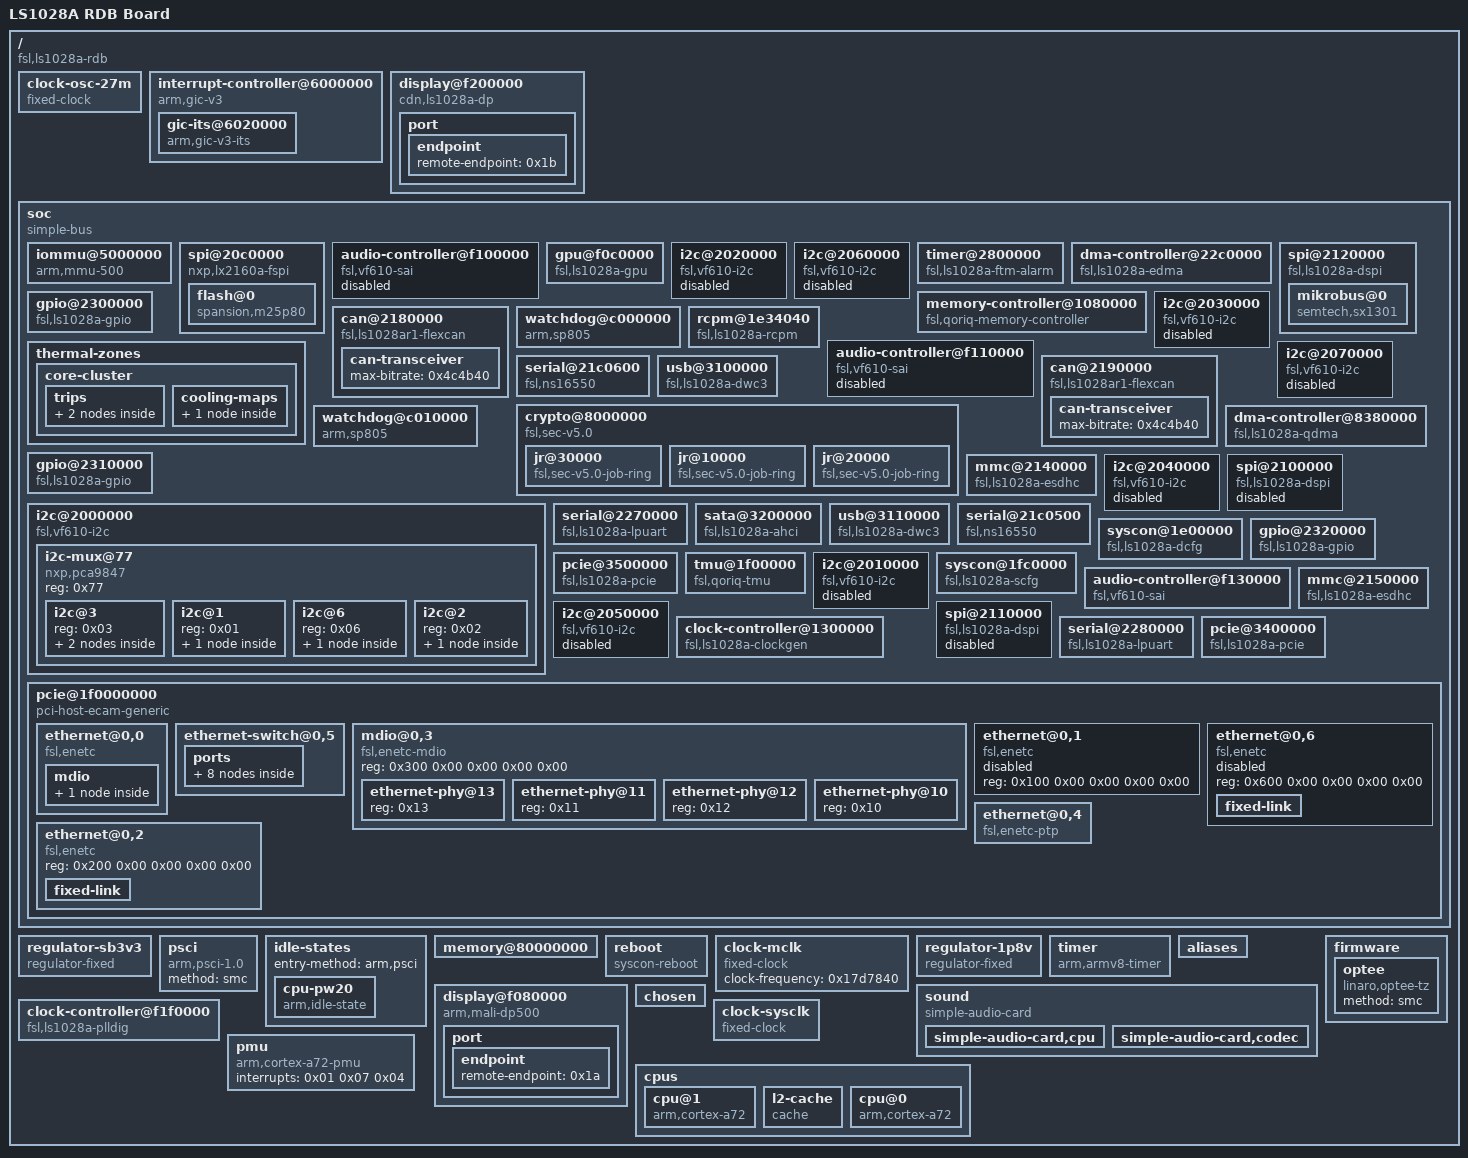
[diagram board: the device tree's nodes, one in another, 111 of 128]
/dts-v1/;

/ {
	#address-cells = <0x02>;
	model = "LS1028A RDB Board";
	#size-cells = <0x02>;
	interrupt-parent = <0x01>;
	compatible = "fsl,ls1028a-rdb\0fsl,ls1028a";

	clock-osc-27m {
		clock-output-names = "phy_27m";
		#clock-cells = <0x00>;
		clock-frequency = <0x19bfcc0>;
		compatible = "fixed-clock";
		phandle = <0x05>;
	};

	interrupt-controller@6000000 {
		#address-cells = <0x02>;
		interrupts = <0x01 0x09 0xf08>;
		#size-cells = <0x02>;
		compatible = "arm,gic-v3";
		ranges;
		#interrupt-cells = <0x03>;
		reg = <0x00 0x6000000 0x00 0x10000 0x00 0x6040000 0x00 0x40000>;
		phandle = <0x01>;
		interrupt-controller;

		gic-its@6020000 {
			msi-controller;
			compatible = "arm,gic-v3-its";
			reg = <0x00 0x6020000 0x00 0x20000>;
			phandle = <0x11>;
		};
	};

	display@f200000 {
		clock-names = "clk_core\0pclk\0sclk\0cclk\0clk_vif\0clk_pxl";
		interrupts = <0x00 0xdd 0x04>;
		clocks = <0x02 0x02 0x02 0x02 0x02 0x02 0x02 0x02 0x02 0x02 0x02 0x02 0x02 0x02 0x02 0x19>;
		compatible = "cdn,ls1028a-dp";
		status = "okay";
		reg = <0x00 0xf200000 0x00 0xfffff>;
		lane-mapping = <0x4e>;

		port {

			endpoint {
				remote-endpoint = <0x1b>;
				phandle = <0x1a>;
			};
		};
	};

	soc {
		#address-cells = <0x02>;
		#size-cells = <0x02>;
		compatible = "simple-bus";
		ranges;

		iommu@5000000 {
			#global-interrupts = <0x08>;
			stream-match-mask = <0x7c00>;
			interrupts = <0x00 0x0d 0x04 0x00 0x0e 0x04 0x00 0x0f 0x04 0x00 0x10 0x04 0x00 0xd3 0x04 0x00 0xd4 0x04 0x00 0xd5 0x04 0x00 0xd6 0x04 0x00 0x92 0x04 0x00 0x93 0x04 0x00 0x94 0x04 0x00 0x95 0x04 0x00 0x96 0x04 0x00 0x97 0x04 0x00 0x98 0x04 0x00 0x99 0x04 0x00 0x9a 0x04 0x00 0x9b 0x04 0x00 0x9c 0x04 0x00 0x9d 0x04 0x00 0x9e 0x04 0x00 0x9f 0x04 0x00 0xa0 0x04 0x00 0xa1 0x04 0x00 0xa2 0x04 0x00 0xa3 0x04 0x00 0xa4 0x04 0x00 0xa5 0x04 0x00 0xa6 0x04 0x00 0xa7 0x04 0x00 0xa8 0x04 0x00 0xa9 0x04 0x00 0xaa 0x04 0x00 0xab 0x04 0x00 0xac 0x04 0x00 0xad 0x04 0x00 0xae 0x04 0x00 0xaf 0x04 0x00 0xb0 0x04 0x00 0xb1 0x04 0x00 0xb2 0x04 0x00 0xb3 0x04 0x00 0xb4 0x04 0x00 0xb5 0x04 0x00 0xb6 0x04 0x00 0xb7 0x04 0x00 0xb8 0x04 0x00 0xb9 0x04 0x00 0xba 0x04 0x00 0xbb 0x04 0x00 0xbc 0x04 0x00 0xbd 0x04 0x00 0xbe 0x04 0x00 0xbf 0x04 0x00 0xc0 0x04 0x00 0xc1 0x04 0x00 0xc2 0x04 0x00 0xc3 0x04 0x00 0xc4 0x04 0x00 0xc5 0x04 0x00 0xc6 0x04 0x00 0xc7 0x04 0x00 0xc8 0x04 0x00 0xc9 0x04 0x00 0xca 0x04 0x00 0xcb 0x04 0x00 0xcc 0x04 0x00 0xcd 0x04 0x00 0xce 0x04 0x00 0xcf 0x04 0x00 0xd0 0x04 0x00 0xd1 0x04>;
			#iommu-cells = <0x01>;
			compatible = "arm,mmu-500";
			reg = <0x00 0x5000000 0x00 0x800000>;
			phandle = <0x10>;
		};

		spi@20c0000 {
			#address-cells = <0x01>;
			clock-names = "fspi_en\0fspi";
			reg-names = "fspi_base\0fspi_mmap";
			interrupts = <0x00 0x19 0x04>;
			clocks = <0x02 0x04 0x03 0x02 0x04 0x03>;
			#size-cells = <0x00>;
			compatible = "nxp,lx2160a-fspi";
			status = "okay";
			reg = <0x00 0x20c0000 0x00 0x10000 0x00 0x20000000 0x00 0x10000000>;

			flash@0 {
				m25p,fast-read;
				#address-cells = <0x01>;
				spi-tx-bus-width = <0x01>;
				#size-cells = <0x01>;
				spi-max-frequency = <0x1312d00>;
				spi-rx-bus-width = <0x08>;
				compatible = "spansion,m25p80";
				reg = <0x00>;
			};
		};

		audio-controller@f100000 {
			clock-names = "bus\0mclk0\0mclk1\0mclk2\0mclk3";
			interrupts = <0x00 0x52 0x04>;
			clocks = <0x02 0x04 0x01 0x02 0x04 0x01 0x02 0x04 0x01 0x02 0x04 0x01 0x02 0x04 0x01>;
			dma-names = "tx\0rx";
			#sound-dai-cells = <0x00>;
			compatible = "fsl,vf610-sai";
			status = "disabled";
			reg = <0x00 0xf100000 0x00 0x10000>;
			dmas = <0x08 0x01 0x04 0x08 0x01 0x03>;
		};

		gpu@f0c0000 {
			iommus = <0x10 0x47>;
			reg-names = "base\0phys_baseaddr\0contiguous_mem";
			interrupts = <0x00 0xdc 0x04>;
			compatible = "fsl,ls1028a-gpu";
			reg = <0x00 0xf0c0000 0x00 0x10000 0x00 0x80000000 0x00 0x80000000 0x00 0x00 0x00 0x3000000>;
		};

		i2c@2020000 {
			#address-cells = <0x01>;
			interrupts = <0x00 0x23 0x04>;
			clocks = <0x02 0x04 0x03>;
			#size-cells = <0x00>;
			compatible = "fsl,vf610-i2c";
			status = "disabled";
			reg = <0x00 0x2020000 0x00 0x10000>;
		};

		i2c@2060000 {
			#address-cells = <0x01>;
			interrupts = <0x00 0x4b 0x04>;
			clocks = <0x02 0x04 0x03>;
			#size-cells = <0x00>;
			compatible = "fsl,vf610-i2c";
			status = "disabled";
			reg = <0x00 0x2060000 0x00 0x10000>;
		};

		timer@2800000 {
			fsl,rcpm-wakeup = <0x18 0x00 0x00 0x00 0x00 0x4000 0x00 0x00>;
			interrupts = <0x00 0x2c 0x04>;
			compatible = "fsl,ls1028a-ftm-alarm";
			reg = <0x00 0x2800000 0x00 0x10000>;
		};

		dma-controller@22c0000 {
			clock-names = "dmamux0\0dmamux1";
			interrupts = <0x00 0x38 0x04 0x00 0x38 0x04>;
			clocks = <0x02 0x04 0x01 0x02 0x04 0x01>;
			compatible = "fsl,ls1028a-edma";
			interrupt-names = "edma-tx\0edma-err";
			reg = <0x00 0x22c0000 0x00 0x10000 0x00 0x22d0000 0x00 0x10000 0x00 0x22e0000 0x00 0x10000>;
			phandle = <0x08>;
			dma-channels = <0x20>;
			#dma-cells = <0x02>;
		};

		memory-controller@1080000 {
			big-endian;
			interrupts = <0x00 0x90 0x04>;
			compatible = "fsl,qoriq-memory-controller";
			reg = <0x00 0x1080000 0x00 0x1000>;
		};

		spi@2120000 {
			#address-cells = <0x01>;
			little-endian;
			clock-names = "dspi";
			spi-num-chipselects = <0x03>;
			interrupts = <0x00 0x1a 0x04>;
			clocks = <0x02 0x04 0x01>;
			#size-cells = <0x00>;
			dma-names = "tx\0rx";
			compatible = "fsl,ls1028a-dspi\0fsl,ls1021a-v1.0-dspi";
			status = "okay";
			bus-num = <0x02>;
			reg = <0x00 0x2120000 0x00 0x10000>;
			dmas = <0x08 0x00 0x36 0x08 0x00 0x02>;

			mikrobus@0 {
				fsl,spi-sck-cs-delay = <0x32>;
				fsl,spi-cs-sck-delay = <0xf4240>;
				spi-max-frequency = <0x1e8480>;
				compatible = "semtech,sx1301";
				reg = <0x00>;
			};
		};

		can@2180000 {
			clock-names = "ipg\0per";
			interrupts = <0x00 0x15 0x04>;
			clocks = <0x07 0x02 0x04 0x01>;
			compatible = "fsl,ls1028ar1-flexcan\0fsl,lx2160ar1-flexcan";
			status = "okay";
			reg = <0x00 0x2180000 0x00 0x10000>;

			can-transceiver {
				max-bitrate = <0x4c4b40>;
			};
		};

		watchdog@c000000 {
			clock-names = "apb_pclk\0wdog_clk";
			clocks = <0x02 0x04 0x0f 0x02 0x04 0x0f>;
			compatible = "arm,sp805\0arm,primecell";
			reg = <0x00 0xc000000 0x00 0x1000>;
		};

		gpio@2300000 {
			little-endian;
			gpio-controller;
			interrupts = <0x00 0x24 0x04>;
			compatible = "fsl,ls1028a-gpio\0fsl,qoriq-gpio";
			#interrupt-cells = <0x02>;
			reg = <0x00 0x2300000 0x00 0x10000>;
			#gpio-cells = <0x02>;
			interrupt-controller;
		};

		rcpm@1e34040 {
			little-endian;
			#fsl,rcpm-wakeup-cells = <0x07>;
			compatible = "fsl,ls1028a-rcpm\0fsl,qoriq-rcpm-2.1+";
			reg = <0x00 0x1e34040 0x00 0x1c>;
			phandle = <0x18>;
		};

		audio-controller@f110000 {
			clock-names = "bus\0mclk0\0mclk1\0mclk2\0mclk3";
			interrupts = <0x00 0x52 0x04>;
			clocks = <0x02 0x04 0x01 0x02 0x04 0x01 0x02 0x04 0x01 0x02 0x04 0x01 0x02 0x04 0x01>;
			dma-names = "tx\0rx";
			#sound-dai-cells = <0x00>;
			compatible = "fsl,vf610-sai";
			status = "disabled";
			reg = <0x00 0xf110000 0x00 0x10000>;
			dmas = <0x08 0x01 0x06 0x08 0x01 0x05>;
		};

		i2c@2030000 {
			#address-cells = <0x01>;
			interrupts = <0x00 0x23 0x04>;
			clocks = <0x02 0x04 0x03>;
			#size-cells = <0x00>;
			compatible = "fsl,vf610-i2c";
			status = "disabled";
			reg = <0x00 0x2030000 0x00 0x10000>;
		};

		thermal-zones {

			core-cluster {
				polling-delay = <0x1388>;
				polling-delay-passive = <0x3e8>;
				thermal-sensors = <0x0c 0x00>;

				trips {

					core-cluster-crit {
						temperature = <0x17318>;
						hysteresis = <0x7d0>;
						type = "critical";
					};

					core-cluster-alert {
						temperature = <0x14c08>;
						hysteresis = <0x7d0>;
						type = "passive";
						phandle = <0x0d>;
					};
				};

				cooling-maps {

					map0 {
						trip = <0x0d>;
						cooling-device = <0x0e 0xffffffff 0xffffffff 0x0f 0xffffffff 0xffffffff>;
					};
				};
			};
		};

		i2c@2070000 {
			#address-cells = <0x01>;
			interrupts = <0x00 0x4b 0x04>;
			clocks = <0x02 0x04 0x03>;
			#size-cells = <0x00>;
			compatible = "fsl,vf610-i2c";
			status = "disabled";
			reg = <0x00 0x2070000 0x00 0x10000>;
		};

		serial@21c0600 {
			interrupts = <0x00 0x20 0x04>;
			clocks = <0x02 0x04 0x01>;
			clock-frequency = <0xbebc200>;
			compatible = "fsl,ns16550\0ns16550a";
			status = "okay";
			reg = <0x00 0x21c0600 0x00 0x100>;
		};

		usb@3100000 {
			iommus = <0x10 0x01>;
			dma-coherent;
			snps,incr-burst-type-adjustment = <0x01 0x04 0x08 0x10>;
			snps,quirk-frame-length-adjustment = <0x20>;
			interrupts = <0x00 0x50 0x04>;
			snps,dis_rxdet_inp3_quirk;
			compatible = "fsl,ls1028a-dwc3\0snps,dwc3";
			reg = <0x00 0x3100000 0x00 0x10000>;
			dr_mode = "host";
		};

		can@2190000 {
			clock-names = "ipg\0per";
			interrupts = <0x00 0x16 0x04>;
			clocks = <0x07 0x02 0x04 0x01>;
			compatible = "fsl,ls1028ar1-flexcan\0fsl,lx2160ar1-flexcan";
			status = "okay";
			reg = <0x00 0x2190000 0x00 0x10000>;

			can-transceiver {
				max-bitrate = <0x4c4b40>;
			};
		};

		crypto@8000000 {
			#address-cells = <0x01>;
			dma-coherent;
			fsl,sec-era = <0x0a>;
			interrupts = <0x00 0x8b 0x04>;
			#size-cells = <0x01>;
			compatible = "fsl,sec-v5.0\0fsl,sec-v4.0";
			ranges = <0x00 0x00 0x8000000 0x100000>;
			reg = <0x00 0x8000000 0x00 0x100000>;

			jr@30000 {
				iommus = <0x10 0x43>;
				interrupts = <0x00 0x8e 0x04>;
				compatible = "fsl,sec-v5.0-job-ring\0fsl,sec-v4.0-job-ring";
				reg = <0x30000 0x10000>;
			};

			jr@10000 {
				iommus = <0x10 0x41>;
				interrupts = <0x00 0x8c 0x04>;
				compatible = "fsl,sec-v5.0-job-ring\0fsl,sec-v4.0-job-ring";
				reg = <0x10000 0x10000>;
			};

			jr@20000 {
				iommus = <0x10 0x42>;
				interrupts = <0x00 0x8d 0x04>;
				compatible = "fsl,sec-v5.0-job-ring\0fsl,sec-v4.0-job-ring";
				reg = <0x20000 0x10000>;
			};
		};

		dma-controller@8380000 {
			iommus = <0x10 0x05>;
			block-offset = <0x10000>;
			block-number = <0x01>;
			status-sizes = <0x40>;
			interrupts = <0x00 0x2b 0x04 0x00 0xfb 0x04 0x00 0xfc 0x04 0x00 0xfd 0x04 0x00 0xfe 0x04>;
			compatible = "fsl,ls1028a-qdma\0fsl,ls1021a-qdma";
			fsl,dma-queues = <0x02>;
			interrupt-names = "qdma-error\0qdma-queue0\0qdma-queue1\0qdma-queue2\0qdma-queue3";
			reg = <0x00 0x8380000 0x00 0x1000 0x00 0x8390000 0x00 0x10000 0x00 0x83a0000 0x00 0x40000>;
			dma-channels = <0x08>;
			queue-sizes = <0x40 0x40>;
		};

		watchdog@c010000 {
			clock-names = "apb_pclk\0wdog_clk";
			clocks = <0x02 0x04 0x0f 0x02 0x04 0x0f>;
			compatible = "arm,sp805\0arm,primecell";
			reg = <0x00 0xc010000 0x00 0x1000>;
		};

		gpio@2310000 {
			little-endian;
			gpio-controller;
			interrupts = <0x00 0x24 0x04>;
			compatible = "fsl,ls1028a-gpio\0fsl,qoriq-gpio";
			#interrupt-cells = <0x02>;
			reg = <0x00 0x2310000 0x00 0x10000>;
			#gpio-cells = <0x02>;
			interrupt-controller;
		};

		i2c@2000000 {
			#address-cells = <0x01>;
			interrupts = <0x00 0x22 0x04>;
			clocks = <0x02 0x04 0x03>;
			#size-cells = <0x00>;
			compatible = "fsl,vf610-i2c";
			status = "okay";
			reg = <0x00 0x2000000 0x00 0x10000>;

			i2c-mux@77 {
				#address-cells = <0x01>;
				#size-cells = <0x00>;
				compatible = "nxp,pca9847";
				reg = <0x77>;

				i2c@3 {
					#address-cells = <0x01>;
					#size-cells = <0x00>;
					reg = <0x03>;

					temperature-sensor@4c {
						compatible = "nxp,sa56004";
						reg = <0x4c>;
						vcc-supply = <0x0b>;
					};

					m41t62@68 {
						compatible = "st,m41t62";
						reg = <0x68>;
					};
				};

				i2c@1 {
					#address-cells = <0x01>;
					#size-cells = <0x00>;
					reg = <0x01>;

					audio-codec@a {
						sclk-strength = <0x03>;
						VDDA-supply = <0x09>;
						clocks = <0x0a>;
						#sound-dai-cells = <0x00>;
						VDDIO-supply = <0x09>;
						compatible = "fsl,sgtl5000";
						reg = <0x0a>;
						phandle = <0x1d>;
					};
				};

				i2c@6 {
					#address-cells = <0x01>;
					#size-cells = <0x00>;
					reg = <0x06>;

					pn7120@28 {
						clock-frequency = <0xf4240>;
						compatible = "nxp,pn7120\0nxp,pn544";
						reg = <0x28>;
					};
				};

				i2c@2 {
					#address-cells = <0x01>;
					#size-cells = <0x00>;
					reg = <0x02>;

					current-monitor@40 {
						compatible = "ti,ina220";
						reg = <0x40>;
						shunt-resistor = <0x1f4>;
					};
				};
			};
		};

		mmc@2140000 {
			iommus = <0x10 0x03>;
			sdhci,auto-cmd12;
			little-endian;
			sd-uhs-sdr25;
			bus-width = <0x04>;
			interrupts = <0x00 0x1c 0x04>;
			clocks = <0x02 0x02 0x01>;
			voltage-ranges = <0x708 0x708 0xce4 0xce4>;
			clock-frequency = <0x17d78400>;
			compatible = "fsl,ls1028a-esdhc\0fsl,esdhc";
			status = "okay";
			reg = <0x00 0x2140000 0x00 0x10000>;
			sd-uhs-sdr104;
			sd-uhs-sdr50;
			sd-uhs-sdr12;
		};

		i2c@2040000 {
			#address-cells = <0x01>;
			interrupts = <0x00 0x4a 0x04>;
			clocks = <0x02 0x04 0x03>;
			#size-cells = <0x00>;
			compatible = "fsl,vf610-i2c";
			status = "disabled";
			reg = <0x00 0x2040000 0x00 0x10000>;
		};

		spi@2100000 {
			#address-cells = <0x01>;
			little-endian;
			clock-names = "dspi";
			spi-num-chipselects = <0x04>;
			interrupts = <0x00 0x1a 0x04>;
			clocks = <0x02 0x04 0x01>;
			#size-cells = <0x00>;
			dma-names = "tx\0rx";
			compatible = "fsl,ls1028a-dspi\0fsl,ls1021a-v1.0-dspi";
			status = "disabled";
			reg = <0x00 0x2100000 0x00 0x10000>;
			dmas = <0x08 0x00 0x3e 0x08 0x00 0x3c>;
		};

		serial@2270000 {
			little-endian;
			clock-names = "ipg";
			interrupts = <0x00 0xe9 0x04>;
			clocks = <0x02 0x04 0x01>;
			compatible = "fsl,ls1028a-lpuart";
			status = "okay";
			reg = <0x00 0x2270000 0x00 0x1000>;
		};

		sata@3200000 {
			iommus = <0x10 0x04>;
			reg-names = "ahci\0sata-ecc";
			interrupts = <0x00 0x85 0x04>;
			clocks = <0x02 0x04 0x01>;
			compatible = "fsl,ls1028a-ahci";
			status = "okay";
			reg = <0x00 0x3200000 0x00 0x10000 0x07 0x100520 0x00 0x04>;
		};

		usb@3110000 {
			iommus = <0x10 0x02>;
			dma-coherent;
			snps,incr-burst-type-adjustment = <0x01 0x04 0x08 0x10>;
			snps,quirk-frame-length-adjustment = <0x20>;
			interrupts = <0x00 0x51 0x04>;
			snps,dis_rxdet_inp3_quirk;
			compatible = "fsl,ls1028a-dwc3\0snps,dwc3";
			reg = <0x00 0x3110000 0x00 0x10000>;
			dr_mode = "otg";
		};

		serial@21c0500 {
			interrupts = <0x00 0x20 0x04>;
			clocks = <0x02 0x04 0x01>;
			clock-frequency = <0xbebc200>;
			compatible = "fsl,ns16550\0ns16550a";
			status = "okay";
			reg = <0x00 0x21c0500 0x00 0x100>;
		};

		syscon@1e00000 {
			little-endian;
			compatible = "fsl,ls1028a-dcfg\0syscon";
			reg = <0x00 0x1e00000 0x00 0x10000>;
			phandle = <0x06>;
		};

		gpio@2320000 {
			little-endian;
			gpio-controller;
			interrupts = <0x00 0x25 0x04>;
			compatible = "fsl,ls1028a-gpio\0fsl,qoriq-gpio";
			#interrupt-cells = <0x02>;
			reg = <0x00 0x2320000 0x00 0x10000>;
			#gpio-cells = <0x02>;
			interrupt-controller;
		};

		pcie@3500000 {
			#address-cells = <0x03>;
			dma-coherent;
			bus-range = <0x00 0xff>;
			reg-names = "regs\0config";
			interrupts = <0x00 0x71 0x04 0x00 0x72 0x04>;
			interrupt-map = <0x00 0x00 0x00 0x01 0x01 0x00 0x00 0x00 0x72 0x04 0x00 0x00 0x00 0x02 0x01 0x00 0x00 0x00 0x73 0x04 0x00 0x00 0x00 0x03 0x01 0x00 0x00 0x00 0x74 0x04 0x00 0x00 0x00 0x04 0x01 0x00 0x00 0x00 0x75 0x04>;
			#size-cells = <0x02>;
			device_type = "pci";
			interrupt-map-mask = <0x00 0x00 0x00 0x07>;
			compatible = "fsl,ls1028a-pcie";
			ranges = <0x81000000 0x00 0x00 0x88 0x10000 0x00 0x10000 0x82000000 0x00 0x40000000 0x88 0x40000000 0x00 0x40000000>;
			msi-map = <0x00 0x11 0x08 0x01 0x100 0x11 0x09 0x01>;
			#interrupt-cells = <0x01>;
			status = "okay";
			interrupt-names = "pme\0aer";
			reg = <0x00 0x3500000 0x00 0x100000 0x88 0x00 0x00 0x2000>;
			iommu-map = <0x00 0x10 0x08 0x01 0x100 0x10 0x09 0x01>;
			msi-parent = <0x11>;
		};

		tmu@1f00000 {
			little-endian;
			fsl,tmu-calibration = <0x00 0x24 0x01 0x2b 0x02 0x31 0x03 0x38 0x04 0x3f 0x05 0x45 0x06 0x4c 0x07 0x53 0x08 0x59 0x09 0x60 0x0a 0x66 0x0b 0x6d 0x10000 0x1c 0x10001 0x24 0x10002 0x2c 0x10003 0x35 0x10004 0x3d 0x10005 0x45 0x10006 0x4d 0x10007 0x55 0x10008 0x5e 0x10009 0x66 0x1000a 0x6e 0x20000 0x18 0x20001 0x22 0x20002 0x2d 0x20003 0x38 0x20004 0x43 0x20005 0x4d 0x20006 0x58 0x20007 0x63 0x20008 0x6e 0x30000 0x10 0x30001 0x1c 0x30002 0x29 0x30003 0x36 0x30004 0x42 0x30005 0x4f 0x30006 0x5b 0x30007 0x68>;
			fsl,tmu-range = <0xb0000 0xa0026 0x80048 0x70061>;
			interrupts = <0x00 0x17 0x04>;
			#thermal-sensor-cells = <0x01>;
			compatible = "fsl,qoriq-tmu";
			reg = <0x00 0x1f80000 0x00 0x10000>;
			phandle = <0x0c>;
		};

		i2c@2010000 {
			#address-cells = <0x01>;
			interrupts = <0x00 0x22 0x04>;
			clocks = <0x02 0x04 0x03>;
			#size-cells = <0x00>;
			compatible = "fsl,vf610-i2c";
			status = "disabled";
			reg = <0x00 0x2010000 0x00 0x10000>;
		};

		syscon@1fc0000 {
			big-endian;
			compatible = "fsl,ls1028a-scfg\0syscon";
			reg = <0x00 0x1fc0000 0x00 0x10000>;
		};

		audio-controller@f130000 {
			clock-names = "bus\0mclk0\0mclk1\0mclk2\0mclk3";
			interrupts = <0x00 0x53 0x04>;
			clocks = <0x02 0x04 0x01 0x02 0x04 0x01 0x02 0x04 0x01 0x02 0x04 0x01 0x02 0x04 0x01>;
			dma-names = "tx\0rx";
			#sound-dai-cells = <0x00>;
			compatible = "fsl,vf610-sai";
			status = "okay";
			reg = <0x00 0xf130000 0x00 0x10000>;
			phandle = <0x1c>;
			dmas = <0x08 0x01 0x0a 0x08 0x01 0x09>;
		};

		mmc@2150000 {
			iommus = <0x10 0x45>;
			sdhci,auto-cmd12;
			little-endian;
			mmc-hs200-1_8v;
			bus-width = <0x08>;
			mmc-hs400-1_8v;
			interrupts = <0x00 0x3f 0x04>;
			clocks = <0x02 0x02 0x01>;
			broken-cd;
			voltage-ranges = <0x708 0x708 0xce4 0xce4>;
			clock-frequency = <0x17d78400>;
			compatible = "fsl,ls1028a-esdhc\0fsl,esdhc";
			status = "okay";
			reg = <0x00 0x2150000 0x00 0x10000>;
		};

		i2c@2050000 {
			#address-cells = <0x01>;
			interrupts = <0x00 0x4a 0x04>;
			clocks = <0x02 0x04 0x03>;
			#size-cells = <0x00>;
			compatible = "fsl,vf610-i2c";
			status = "disabled";
			reg = <0x00 0x2050000 0x00 0x10000>;
		};

		clock-controller@1300000 {
			clocks = <0x07>;
			#clock-cells = <0x02>;
			compatible = "fsl,ls1028a-clockgen";
			reg = <0x00 0x1300000 0x00 0xa0000>;
			phandle = <0x02>;
		};

		spi@2110000 {
			#address-cells = <0x01>;
			little-endian;
			clock-names = "dspi";
			spi-num-chipselects = <0x04>;
			interrupts = <0x00 0x1a 0x04>;
			clocks = <0x02 0x04 0x01>;
			#size-cells = <0x00>;
			dma-names = "tx\0rx";
			compatible = "fsl,ls1028a-dspi\0fsl,ls1021a-v1.0-dspi";
			status = "disabled";
			reg = <0x00 0x2110000 0x00 0x10000>;
			dmas = <0x08 0x00 0x3a 0x08 0x00 0x38>;
		};

		serial@2280000 {
			little-endian;
			clock-names = "ipg";
			interrupts = <0x00 0xea 0x04>;
			clocks = <0x02 0x04 0x01>;
			compatible = "fsl,ls1028a-lpuart";
			status = "okay";
			reg = <0x00 0x2280000 0x00 0x1000>;
		};

		pcie@3400000 {
			#address-cells = <0x03>;
			dma-coherent;
			bus-range = <0x00 0xff>;
			reg-names = "regs\0config";
			interrupts = <0x00 0x6c 0x04 0x00 0x6d 0x04>;
			interrupt-map = <0x00 0x00 0x00 0x01 0x01 0x00 0x00 0x00 0x6d 0x04 0x00 0x00 0x00 0x02 0x01 0x00 0x00 0x00 0x6e 0x04 0x00 0x00 0x00 0x03 0x01 0x00 0x00 0x00 0x6f 0x04 0x00 0x00 0x00 0x04 0x01 0x00 0x00 0x00 0x70 0x04>;
			#size-cells = <0x02>;
			device_type = "pci";
			interrupt-map-mask = <0x00 0x00 0x00 0x07>;
			compatible = "fsl,ls1028a-pcie";
			ranges = <0x81000000 0x00 0x00 0x80 0x10000 0x00 0x10000 0x82000000 0x00 0x40000000 0x80 0x40000000 0x00 0x40000000>;
			msi-map = <0x00 0x11 0x07 0x01>;
			#interrupt-cells = <0x01>;
			status = "okay";
			interrupt-names = "pme\0aer";
			reg = <0x00 0x3400000 0x00 0x100000 0x80 0x00 0x00 0x2000>;
			iommu-map = <0x00 0x10 0x07 0x01>;
			msi-parent = <0x11>;
		};

		pcie@1f0000000 {
			#address-cells = <0x03>;
			dma-coherent;
			bus-range = <0x00 0x00>;
			#size-cells = <0x02>;
			device_type = "pci";
			compatible = "pci-host-ecam-generic";
			ranges = <0x82000000 0x00 0x00 0x01 0xf8000000 0x00 0x160000 0xc2000000 0x00 0x00 0x01 0xf8160000 0x00 0x70000 0x82000000 0x00 0x00 0x01 0xf81d0000 0x00 0x20000 0xc2000000 0x00 0x00 0x01 0xf81f0000 0x00 0x20000 0x82000000 0x00 0x00 0x01 0xf8210000 0x00 0x20000 0xc2000000 0x00 0x00 0x01 0xf8230000 0x00 0x20000 0x82000000 0x00 0x00 0x01 0xfc000000 0x00 0x400000>;
			msi-map = <0x00 0x11 0x20 0x0c>;
			reg = <0x01 0xf0000000 0x00 0x100000>;
			iommu-map = <0x00 0x10 0x20 0x0c>;
			msi-parent = <0x11>;

			ethernet@0,0 {
				phy-connection-type = "sgmii";
				compatible = "fsl,enetc";
				reg = <0x00 0x00 0x00 0x00 0x00>;
				phy-handle = <0x12>;

				mdio {
					#address-cells = <0x01>;
					#size-cells = <0x00>;

					ethernet-phy@2 {
						reg = <0x02>;
						phandle = <0x12>;
					};
				};
			};

			ethernet-switch@0,5 {
				interrupts = <0x00 0x5f 0x04>;
				status = "okay";
				reg = <0x500 0x00 0x00 0x00 0x00>;

				ports {
					#address-cells = <0x01>;
					#size-cells = <0x00>;

					port@0 {
						phy-mode = "qsgmii";
						label = "swp0";
						status = "okay";
						managed = "in-band-status";
						reg = <0x00>;
						phy-handle = <0x13>;
					};

					port@5 {
						phy-mode = "internal";
						status = "disabled";
						reg = <0x05>;

						fixed-link {
							full-duplex;
							speed = <0x3e8>;
						};
					};

					port@3 {
						phy-mode = "qsgmii";
						label = "swp3";
						status = "okay";
						managed = "in-band-status";
						reg = <0x03>;
						phy-handle = <0x16>;
					};

					port@1 {
						phy-mode = "qsgmii";
						label = "swp1";
						status = "okay";
						managed = "in-band-status";
						reg = <0x01>;
						phy-handle = <0x14>;
					};

					port@4 {
						phy-mode = "internal";
						reg = <0x04>;
						ethernet = <0x17>;

						fixed-link {
							full-duplex;
							speed = <0x9c4>;
						};
					};

					port@2 {
						phy-mode = "qsgmii";
						label = "swp2";
						status = "okay";
						managed = "in-band-status";
						reg = <0x02>;
						phy-handle = <0x15>;
					};
				};
			};

			mdio@0,3 {
				#address-cells = <0x01>;
				#size-cells = <0x00>;
				compatible = "fsl,enetc-mdio";
				reg = <0x300 0x00 0x00 0x00 0x00>;

				ethernet-phy@13 {
					reg = <0x13>;
					phandle = <0x16>;
				};

				ethernet-phy@11 {
					reg = <0x11>;
					phandle = <0x14>;
				};

				ethernet-phy@12 {
					reg = <0x12>;
					phandle = <0x15>;
				};

				ethernet-phy@10 {
					reg = <0x10>;
					phandle = <0x13>;
				};
			};

			ethernet@0,1 {
				compatible = "fsl,enetc";
				status = "disabled";
				reg = <0x100 0x00 0x00 0x00 0x00>;
			};

			ethernet@0,6 {
				compatible = "fsl,enetc";
				status = "disabled";
				reg = <0x600 0x00 0x00 0x00 0x00>;

				fixed-link {
					full-duplex;
					speed = <0x3e8>;
				};
			};

			ethernet@0,4 {
				little-endian;
				clocks = <0x02 0x04 0x00>;
				compatible = "fsl,enetc-ptp";
				reg = <0x400 0x00 0x00 0x00 0x00>;
			};

			ethernet@0,2 {
				compatible = "fsl,enetc";
				reg = <0x200 0x00 0x00 0x00 0x00>;
				phandle = <0x17>;

				fixed-link {
					full-duplex;
					speed = <0x3e8>;
				};
			};
		};
	};

	regulator-sb3v3 {
		regulator-max-microvolt = <0x325aa0>;
		regulator-boot-on;
		regulator-always-on;
		regulator-min-microvolt = <0x325aa0>;
		regulator-name = "3v3_vbus";
		compatible = "regulator-fixed";
		phandle = <0x0b>;
	};

	psci {
		method = "smc";
		compatible = "arm,psci-1.0\0arm,psci-0.2";
		status = "okay";
	};

	idle-states {
		entry-method = "arm,psci";

		cpu-pw20 {
			entry-latency-us = <0x7d0>;
			idle-state-name = "PW20";
			exit-latency-us = <0x7d0>;
			arm,psci-suspend-param = <0x00>;
			compatible = "arm,idle-state";
			phandle = <0x04>;
			min-residency-us = <0x1770>;
		};
	};

	memory@80000000 {
		device_type = "memory";
		reg = <0x00 0x80000000 0x00 0x7be00000 0x20 0x80000000 0x00 0x80000000>;
	};

	reboot {
		mask = <0x02>;
		offset = <0xb0>;
		compatible = "syscon-reboot";
		regmap = <0x06>;
	};

	clock-mclk {
		#clock-cells = <0x00>;
		clock-frequency = <0x17d7840>;
		compatible = "fixed-clock";
		phandle = <0x0a>;
	};

	regulator-1p8v {
		regulator-max-microvolt = <0x1b7740>;
		regulator-always-on;
		regulator-min-microvolt = <0x1b7740>;
		regulator-name = "1P8V";
		compatible = "regulator-fixed";
		phandle = <0x09>;
	};

	timer {
		interrupts = <0x01 0x0d 0x308 0x01 0x0e 0x308 0x01 0x0b 0x308 0x01 0x0a 0x308>;
		compatible = "arm,armv8-timer";
	};

	aliases {
		crypto = "/soc/crypto@8000000";
		serial1 = "/soc/serial@21c0600";
		rtc1 = "/soc/timer@2800000";
		serial0 = "/soc/serial@21c0500";
	};

	sound {
		simple-audio-card,format = "i2s";
		simple-audio-card,widgets = "Microphone\0Microphone Jack\0Headphone\0Headphone Jack\0Speaker\0Speaker Ext\0Line\0Line In Jack";
		simple-audio-card,routing = "MIC_IN\0Microphone Jack\0Microphone Jack\0Mic Bias\0LINE_IN\0Line In Jack\0Headphone Jack\0HP_OUT\0Speaker Ext\0LINE_OUT";
		compatible = "simple-audio-card";

		simple-audio-card,cpu {
			frame-master;
			bitclock-master;
			sound-dai = <0x1c>;
		};

		simple-audio-card,codec {
			frame-master;
			bitclock-master;
			sound-dai = <0x1d>;
			system-clock-frequency = <0x17d7840>;
		};
	};

	firmware {

		optee {
			method = "smc";
			compatible = "linaro,optee-tz";
		};
	};

	display@f080000 {
		iommus = <0x10 0x48>;
		arm,malidp-output-port-lines = [08 08 08];
		clock-names = "pxlclk\0mclk\0aclk\0pclk";
		interrupts = <0x00 0xde 0x04 0x00 0xdf 0x04>;
		clocks = <0x19 0x02 0x02 0x02 0x02 0x02 0x02 0x02 0x02 0x02>;
		arm,malidp-arqos-value = <0xd000d000>;
		compatible = "arm,mali-dp500";
		interrupt-names = "DE\0SE";
		reg = <0x00 0xf080000 0x00 0x10000>;

		port {

			endpoint {
				remote-endpoint = <0x1a>;
				phandle = <0x1b>;
			};
		};
	};

	clock-controller@f1f0000 {
		clocks = <0x05>;
		#clock-cells = <0x00>;
		compatible = "fsl,ls1028a-plldig";
		reg = <0x00 0xf1f0000 0x00 0xffff>;
		phandle = <0x19>;
	};

	chosen {
		bootargs = "root=/dev/mmcblk1p2 rootwait rw earlycon=uart8250,0x21c0500 console=ttyS0,115200 cma=256M video=1920x1080-32@60";
		kaslr-seed = <0x00 0x00>;
		linux,stdout-path = "/soc/serial@21c0500";
		stdout-path = "serial0:115200n8";
	};

	clock-sysclk {
		clock-output-names = "sysclk";
		#clock-cells = <0x00>;
		clock-frequency = <0x5f5e100>;
		compatible = "fixed-clock";
		phandle = <0x07>;
	};

	pmu {
		interrupts = <0x01 0x07 0x04>;
		compatible = "arm,cortex-a72-pmu";
	};

	cpus {
		#address-cells = <0x01>;
		#size-cells = <0x00>;

		cpu@1 {
			clocks = <0x02 0x01 0x00>;
			cpu-idle-states = <0x04>;
			device_type = "cpu";
			compatible = "arm,cortex-a72";
			next-level-cache = <0x03>;
			reg = <0x01>;
			enable-method = "psci";
			phandle = <0x0f>;
			#cooling-cells = <0x02>;
		};

		l2-cache {
			compatible = "cache";
			phandle = <0x03>;
		};

		cpu@0 {
			clocks = <0x02 0x01 0x00>;
			cpu-idle-states = <0x04>;
			device_type = "cpu";
			compatible = "arm,cortex-a72";
			next-level-cache = <0x03>;
			reg = <0x00>;
			enable-method = "psci";
			phandle = <0x0e>;
			#cooling-cells = <0x02>;
		};
	};
};
